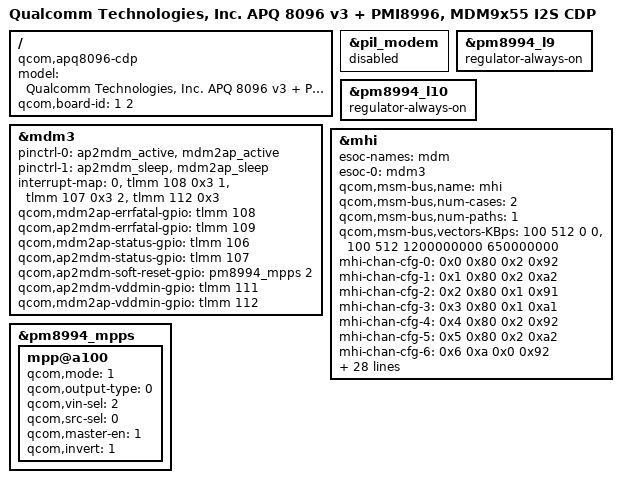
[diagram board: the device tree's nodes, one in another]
/* Copyright (c) 2015-2016, The Linux Foundation. All rights reserved.
 *
 * This program is free software; you can redistribute it and/or modify
 * it under the terms of the GNU General Public License version 2 and
 * only version 2 as published by the Free Software Foundation.
 *
 * This program is distributed in the hope that it will be useful,
 * but WITHOUT ANY WARRANTY; without even the implied warranty of
 * MERCHANTABILITY or FITNESS FOR A PARTICULAR PURPOSE.  See the
 * GNU General Public License for more details.
 */


/dts-v1/;

#include "apq8096-v3.dtsi"
#include "msm-pmi8996.dtsi"
#include "msm8996-cdp.dtsi"
#include "external-soc.dtsi"

/ {
	model = "Qualcomm Technologies, Inc. APQ 8096 v3 + PMI8996, MDM9x55 I2S CDP";
	compatible = "qcom,apq8096-cdp", "qcom,apq8096", "qcom,cdp";
	qcom,board-id = <1 2>;
};

&pil_modem {
	status = "disabled";
};

&pm8994_l9 {
	regulator-always-on;
};

&pm8994_l10 {
	regulator-always-on;
};

&mdm3 {
	pinctrl-names = "mdm_active", "mdm_suspend";
	pinctrl-0 = <&ap2mdm_active &mdm2ap_active>;
	pinctrl-1 = <&ap2mdm_sleep &mdm2ap_sleep>;
	interrupt-map = <0 &tlmm 108 0x3
			1 &tlmm 107 0x3
			2 &tlmm 112 0x3>;
	qcom,mdm2ap-errfatal-gpio = <&tlmm 108 0x00>;
	qcom,ap2mdm-errfatal-gpio = <&tlmm 109 0x00>;
	qcom,mdm2ap-status-gpio   = <&tlmm 106 0x00>;
	qcom,ap2mdm-status-gpio   = <&tlmm 107 0x00>;
	qcom,ap2mdm-soft-reset-gpio = <&pm8994_mpps 2 0>;
	qcom,ap2mdm-vddmin-gpio = <&tlmm 111 0x00>;
	qcom,mdm2ap-vddmin-gpio = <&tlmm 112 0x00>;
	status = "ok";
};

&mhi {
	esoc-names = "mdm";
	esoc-0 = <&mdm3>;
	qcom,msm-bus,name = "mhi";
	qcom,msm-bus,num-cases = <2>;
	qcom,msm-bus,num-paths = <1>;
	qcom,msm-bus,vectors-KBps =
		<100 512 0 0>,
		<100 512 1200000000 650000000>;
	mhi-chan-cfg-0 = <0x0 0x80 0x2 0x92>;
	mhi-chan-cfg-1 = <0x1 0x80 0x2 0xa2>;
	mhi-chan-cfg-2 = <0x2 0x80 0x1 0x91>;
	mhi-chan-cfg-3 = <0x3 0x80 0x1 0xa1>;
	mhi-chan-cfg-4 = <0x4 0x80 0x2 0x92>;
	mhi-chan-cfg-5 = <0x5 0x80 0x2 0xa2>;
	mhi-chan-cfg-6 = <0x6 0xa 0x0 0x92>;
	mhi-chan-cfg-7 = <0x7 0xa 0x0 0xa2>;
	mhi-chan-cfg-10 = <0xa 0x80 0x1 0x92>;
	mhi-chan-cfg-11 = <0xb 0x80 0x1 0xa2>;
	mhi-chan-cfg-14 = <0xe 0x40 0x1 0x92>;
	mhi-chan-cfg-15 = <0xf 0x40 0x1 0xa2>;
	mhi-chan-cfg-16 = <0x10 0x40 0x1 0x92>;
	mhi-chan-cfg-17 = <0x11 0x40 0x1 0xa2>;
	mhi-chan-cfg-18 = <0x12 0x40 0x1 0x92>;
	mhi-chan-cfg-19 = <0x13 0x40 0x1 0xa2>;
	mhi-chan-cfg-20 = <0x14 0xa 0x0 0x92>;
	mhi-chan-cfg-21 = <0x15 0xa 0x0 0xa2>;
	mhi-chan-cfg-22 = <0x16 0xa 0x0 0x92>;
	mhi-chan-cfg-23 = <0x17 0xa 0x0 0xa2>;
	mhi-chan-cfg-24 = <0x18 0xa 0x0 0x91>;
	mhi-chan-cfg-25 = <0x19 0xa 0x0 0xa1>;
	mhi-chan-cfg-32 = <0x20 0x80 0x2 0x92>;
	mhi-chan-cfg-33 = <0x21 0x80 0x2 0xa2>;
	mhi-chan-cfg-34 = <0x22 0x80 0x2 0x92>;
	mhi-chan-cfg-35 = <0x23 0x80 0x2 0xa2>;
	mhi-chan-cfg-100 = <0x64 0x80 0x3 0x52>;
	mhi-chan-cfg-101 = <0x65 0x80 0x4 0x62>;
	mhi-event-rings = <5>;
	mhi-event-cfg-0 = <0x80 0x0 0x1 0x11>;
	mhi-event-cfg-1 = <0x80 0x1 0x1 0x11>;
	mhi-event-cfg-2 = <0x80 0x2 0x5 0x11>;
	mhi-event-cfg-3 = <0x100 0x3 0x1 0x9>;
	mhi-event-cfg-4 = <0x100 0x4 0x1 0x8>;
	mhi-dev-address-win-size = <0x10 0x00000000>;
};

&pm8994_mpps {
	mpp@a100 { /* MPP 2*/
		/* MDM PON conrol*/
		qcom,mode = <1>;		/* Digital output */
		qcom,output-type = <0>;		/* CMOS logic */
		qcom,vin-sel = <2>;		/* S4 1.8V */
		qcom,src-sel = <0>;		/* Constant */
		qcom,master-en = <1>;		/* Enable GPIO */
		qcom,invert = <1>;
		status = "okay";
	};
};
